# ipro7 register map
Vendor: intelpro; Series: BTBLE
CPU: ipro7, little endian
Registers are 32-bit, read-write, reset 0x0 unless marked. A register's access mark holds for its fields unless they carry their own. Offsets are from the block's base; [hi:lo] are bit positions; {n}, {i} and the like mark numbered series.

## RF
Base 0x30001000
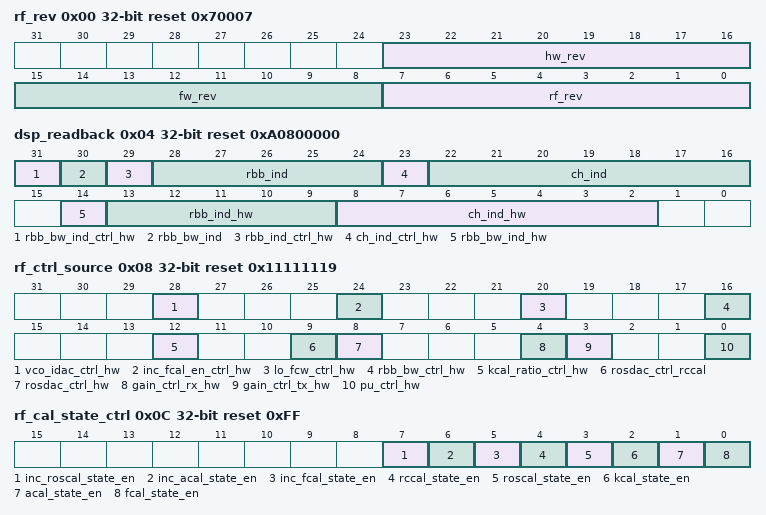
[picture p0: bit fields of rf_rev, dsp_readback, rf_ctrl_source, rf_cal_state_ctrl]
0x00 rf_rev reset 0x70007 (reset mask 0xFF000000) — Silicon revision
  [23:16] hw_rev ro — mark digital HW REV ID
  [15:8] fw_rev ro — mark firmware REV ID
  [7:0] rf_rev ro — mark RF IP rev ID
0x04 dsp_readback reset 0xA0800000 (reset mask 0xFFFF8003)
  [31] rbb_bw_ind_ctrl_hw
  [30] rbb_bw_ind — 0: 1M mode, 1: 2M mode
  [29] rbb_ind_ctrl_hw
  [28:24] rbb_ind — 0: -12dB, 15: 18dB
  [23] ch_ind_ctrl_hw
  [22:16] ch_ind — 0: 2400MHz, 80: 2480MHz
  [14] rbb_bw_ind_hw ro — 0: 1M mode, 1: 2M mode
  [13:9] rbb_ind_hw ro — 0: -12dB, 15: 18dB
  [8:2] ch_ind_hw ro — 0: 2400MHz, 80: 2480MHz
0x08 rf_ctrl_source reset 0x11111119 — Control logic switch
  [28] vco_idac_ctrl_hw — 1: vco_idac input is controlled by dsp 0: vco_idac input is controlled by register
  [24] inc_fcal_en_ctrl_hw — 1: inc_fcal_en input is controlled by dsp 0: inc_fcal_en input is controlled by register
  [20] lo_fcw_ctrl_hw — 1: lo_fcw input is controlled by dsp 0: lo_fcw input is controlled by register
  [16] rbb_bw_ctrl_hw — 1: rbb_bw input is controlled by dsp 0: rbb_bw input is controlled by register
  [12] kcal_ratio_ctrl_hw — 1: kcal_ratio input is controlled by dsp 0: kcal_ratio input is controlled by register
  [9] rosdac_ctrl_rccal — 1: dsp control of rosdac from singen 0: dsp control of rosdac from gain table
  [8] rosdac_ctrl_hw — 1: rosdac input is controlled by dsp 0: rosdac input is controlled by register
  [4] gain_ctrl_rx_hw — 1: RX gain control are controlled by hardware logic input, ex gx_xxx_hw 0: RX gain control bits are controlled by this register map gc_xxx value
  [3] gain_ctrl_tx_hw — 1: TX gain control are controlled by hardware logic input, ex gx_xxx_hw 0: TX gain control bits are controlled by this register map gc_xxx value
  [0] pu_ctrl_hw — 1: pu control bits are controlled by hardware logic input ex: pu_xxx_hw 0: pu control bits are controlled by pu_xxx in this registermap
0x0C rf_cal_state_ctrl reset 0xFF — rf calibration state enable in full cal list
  [7] inc_roscal_state_en — 1'b1: perform inc_roscal
  [6] inc_acal_state_en — 1'b1: perform inc_acal
  [5] inc_fcal_state_en — 1'b1: perform inc_fcal
  [4] rccal_state_en — 1'b1: perform rccal
  [3] roscal_state_en — 1'b1: perform roscal
  [2] kcal_state_en — 1'b1: perform kal
  [1] acal_state_en — 1'b1: perform acal
  [0] fcal_state_en — 1'b1: perform fcal
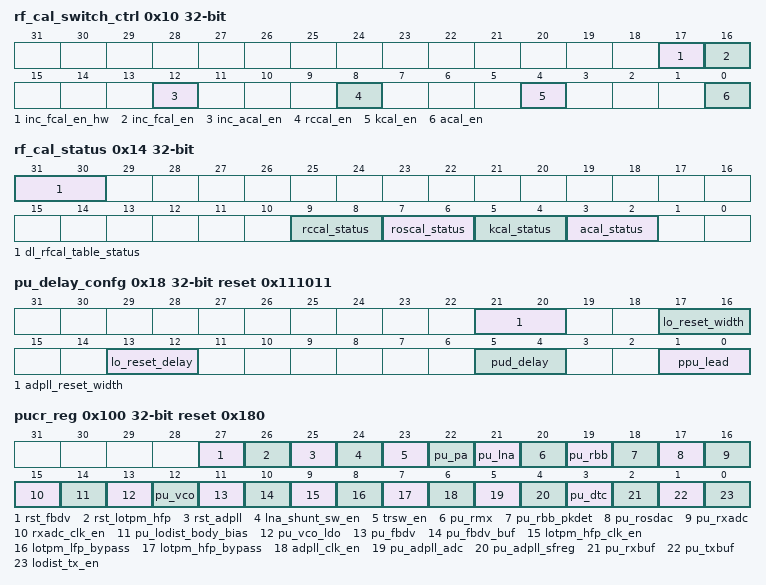
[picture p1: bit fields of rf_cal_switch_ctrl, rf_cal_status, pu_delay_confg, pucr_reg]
0x10 rf_cal_switch_ctrl (reset mask 0xFFFDFFFF) — Calibration mode register
  [17] inc_fcal_en_hw ro
  [16] inc_fcal_en — valid when inc_fcal_en_ctrl_hw=0
  [12] inc_acal_en
  [8] rccal_en
  [4] kcal_en
  [0] acal_en
0x14 rf_cal_status
  [31:30] dl_rfcal_table_status — no calibration, just download RFCAL table status : 0: not started, 1: on-going, 2: fail, 3:pass
  [9:8] rccal_status — 0: not started, 1: on-going, 2: fail, 3:pass
  [7:6] roscal_status — 0: not started, 1: on-going, 2: fail, 3:pass
  [5:4] kcal_status — 0: not started, 1: on-going, 2: fail, 3:pass
  [3:2] acal_status — 0: not started, 1: on-going, 2: fail, 3:pass
0x18 pu_delay_confg reset 0x111011
  [21:20] adpll_reset_width — pulse width of rst_adpll 0: 0.4us, 1: 0.8us, 2: 1.2us, 3: 1.6us
  [17:16] lo_reset_width — pulse width of rst_fbdv/rst_lotpm_hfp/rst_lotpm_lfp 0: 0.1us, 1: 0.2us, 2: 0.3us, 3: 0.4us
  [13:12] lo_reset_delay — lo reset delay WRT ppu_vco 0: 0.4us 1: 0.8us 2: 1.2us 3 1.6us
  [5:4] pud_delay — PUD signal delay with respect to PU 2'b00: 2 us 2'b01: 4 us 2'b10: 6 us 2'b11: 8 us
  [1:0] ppu_lead — PPU signal lead to PU signal 2'b00: 0.2 us 2'b01: 0.4 us 2'b10: 0.6 us 2'b11: 0.8 us
0x100 pucr_reg reset 0x180 — Register control of power up signals
  [27] rst_fbdv — register control, valid when pu_ctrl_hw=0
  [26] rst_lotpm_hfp
  [25] rst_adpll
  [24] lna_shunt_sw_en — 1: ~15dB rx gain att 0: normal mode
  [23] trsw_en — 1: RX mode 0:TX mode
  [22] pu_pa
  [21] pu_lna
  [20] pu_rmx
  [19] pu_rbb
  [18] pu_rbb_pkdet
  [17] pu_rosdac
  [16] pu_rxadc
  [15] rxadc_clk_en
  [14] pu_lodist_body_bias
  [13] pu_vco_ldo
  [12] pu_vco
  [11] pu_fbdv
  [10] pu_fbdv_buf
  [9] lotpm_hfp_clk_en
  [8] lotpm_lfp_bypass
  [7] lotpm_hfp_bypass
  [6] adpll_clk_en
  [5] pu_adpll_adc
  [4] pu_adpll_sfreg
  [3] pu_dtc
  [2] pu_rxbuf
  [1] pu_txbuf
  [0] lodist_tx_en
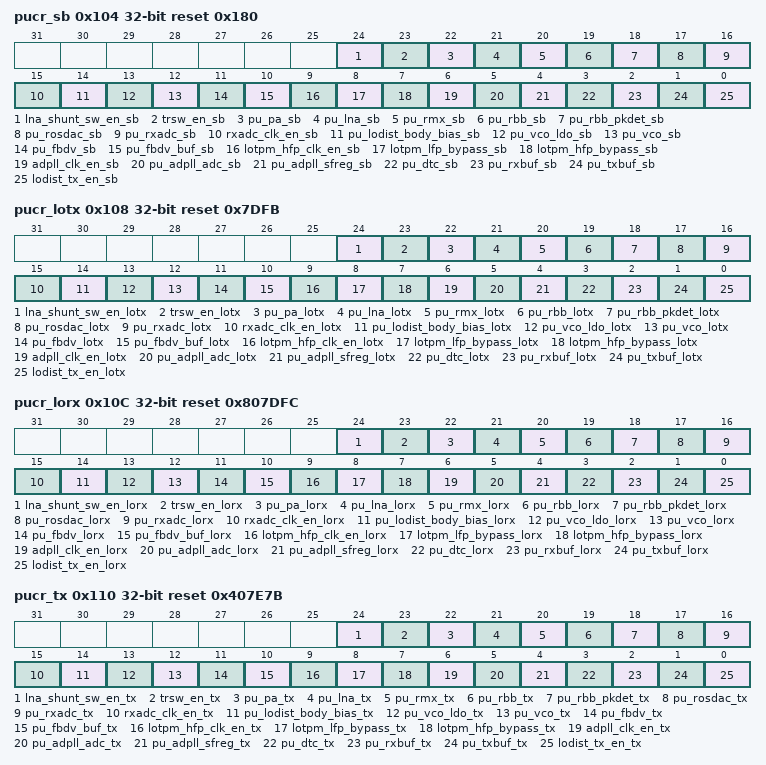
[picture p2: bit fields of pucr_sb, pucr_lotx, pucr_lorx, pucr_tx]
0x104 pucr_sb reset 0x180 — Power up setting in SB state
  [24] lna_shunt_sw_en_sb — 1: ~15dB rx gain att 0: normal mode
  [23] trsw_en_sb
  [22] pu_pa_sb
  [21] pu_lna_sb
  [20] pu_rmx_sb
  [19] pu_rbb_sb
  [18] pu_rbb_pkdet_sb
  [17] pu_rosdac_sb
  [16] pu_rxadc_sb
  [15] rxadc_clk_en_sb
  [14] pu_lodist_body_bias_sb
  [13] pu_vco_ldo_sb
  [12] pu_vco_sb
  [11] pu_fbdv_sb
  [10] pu_fbdv_buf_sb
  [9] lotpm_hfp_clk_en_sb
  [8] lotpm_lfp_bypass_sb
  [7] lotpm_hfp_bypass_sb
  [6] adpll_clk_en_sb
  [5] pu_adpll_adc_sb
  [4] pu_adpll_sfreg_sb
  [3] pu_dtc_sb
  [2] pu_rxbuf_sb
  [1] pu_txbuf_sb
  [0] lodist_tx_en_sb
0x108 pucr_lotx reset 0x7DFB — Power up in LOTX state
  [24] lna_shunt_sw_en_lotx — 1: ~15dB rx gain att 0: normal mode
  [23] trsw_en_lotx
  [22] pu_pa_lotx
  [21] pu_lna_lotx
  [20] pu_rmx_lotx
  [19] pu_rbb_lotx
  [18] pu_rbb_pkdet_lotx
  [17] pu_rosdac_lotx
  [16] pu_rxadc_lotx
  [15] rxadc_clk_en_lotx
  [14] pu_lodist_body_bias_lotx
  [13] pu_vco_ldo_lotx
  [12] pu_vco_lotx
  [11] pu_fbdv_lotx
  [10] pu_fbdv_buf_lotx
  [9] lotpm_hfp_clk_en_lotx
  [8] lotpm_lfp_bypass_lotx
  [7] lotpm_hfp_bypass_lotx
  [6] adpll_clk_en_lotx
  [5] pu_adpll_adc_lotx
  [4] pu_adpll_sfreg_lotx
  [3] pu_dtc_lotx
  [2] pu_rxbuf_lotx
  [1] pu_txbuf_lotx
  [0] lodist_tx_en_lotx
0x10C pucr_lorx reset 0x807DFC — Power up in LORX state
  [24] lna_shunt_sw_en_lorx — 1: ~15dB rx gain att 0: normal mode
  [23] trsw_en_lorx
  [22] pu_pa_lorx
  [21] pu_lna_lorx
  [20] pu_rmx_lorx
  [19] pu_rbb_lorx
  [18] pu_rbb_pkdet_lorx
  [17] pu_rosdac_lorx
  [16] pu_rxadc_lorx
  [15] rxadc_clk_en_lorx
  [14] pu_lodist_body_bias_lorx
  [13] pu_vco_ldo_lorx
  [12] pu_vco_lorx
  [11] pu_fbdv_lorx
  [10] pu_fbdv_buf_lorx
  [9] lotpm_hfp_clk_en_lorx
  [8] lotpm_lfp_bypass_lorx
  [7] lotpm_hfp_bypass_lorx
  [6] adpll_clk_en_lorx
  [5] pu_adpll_adc_lorx
  [4] pu_adpll_sfreg_lorx
  [3] pu_dtc_lorx
  [2] pu_rxbuf_lorx
  [1] pu_txbuf_lorx
  [0] lodist_tx_en_lorx
0x110 pucr_tx reset 0x407E7B — Power up in TX state
  [24] lna_shunt_sw_en_tx — 1: ~15dB rx gain att 0: normal mode
  [23] trsw_en_tx
  [22] pu_pa_tx
  [21] pu_lna_tx
  [20] pu_rmx_tx
  [19] pu_rbb_tx
  [18] pu_rbb_pkdet_tx
  [17] pu_rosdac_tx
  [16] pu_rxadc_tx
  [15] rxadc_clk_en_tx
  [14] pu_lodist_body_bias_tx
  [13] pu_vco_ldo_tx
  [12] pu_vco_tx
  [11] pu_fbdv_tx
  [10] pu_fbdv_buf_tx
  [9] lotpm_hfp_clk_en_tx
  [8] lotpm_lfp_bypass_tx
  [7] lotpm_hfp_bypass_tx
  [6] adpll_clk_en_tx
  [5] pu_adpll_adc_tx
  [4] pu_adpll_sfreg_tx
  [3] pu_dtc_tx
  [2] pu_rxbuf_tx
  [1] pu_txbuf_tx
  [0] lodist_tx_en_tx
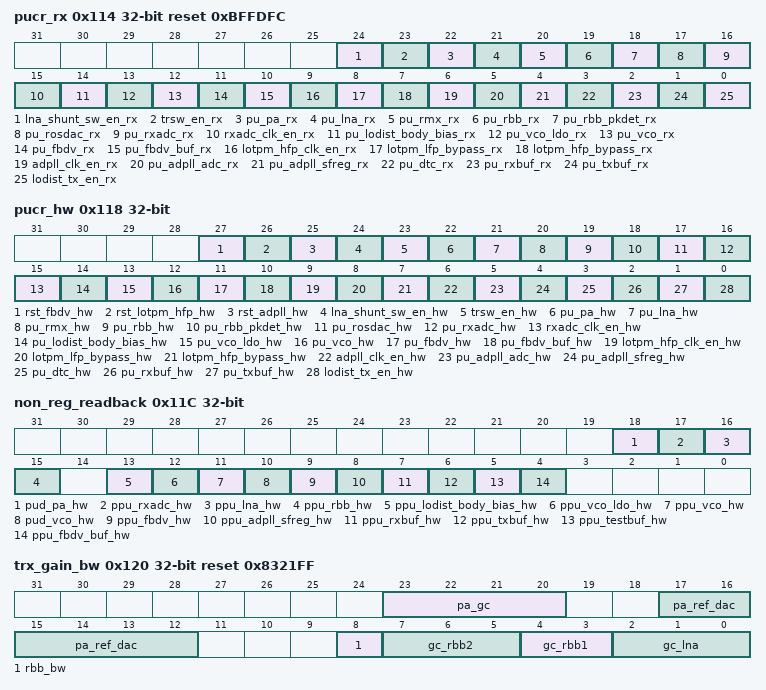
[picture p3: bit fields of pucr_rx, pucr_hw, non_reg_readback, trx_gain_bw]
0x114 pucr_rx reset 0xBFFDFC — Power up in RX state
  [24] lna_shunt_sw_en_rx — 1: ~15dB rx gain att 0: normal mode
  [23] trsw_en_rx
  [22] pu_pa_rx
  [21] pu_lna_rx
  [20] pu_rmx_rx
  [19] pu_rbb_rx
  [18] pu_rbb_pkdet_rx
  [17] pu_rosdac_rx
  [16] pu_rxadc_rx
  [15] rxadc_clk_en_rx
  [14] pu_lodist_body_bias_rx
  [13] pu_vco_ldo_rx
  [12] pu_vco_rx
  [11] pu_fbdv_rx
  [10] pu_fbdv_buf_rx
  [9] lotpm_hfp_clk_en_rx
  [8] lotpm_lfp_bypass_rx
  [7] lotpm_hfp_bypass_rx
  [6] adpll_clk_en_rx
  [5] pu_adpll_adc_rx
  [4] pu_adpll_sfreg_rx
  [3] pu_dtc_rx
  [2] pu_rxbuf_rx
  [1] pu_txbuf_rx
  [0] lodist_tx_en_rx
0x118 pucr_hw (reset mask 0xF0000000) — Hardware read back of power up signals
  [27] rst_fbdv_hw ro — hardware read back
  [26] rst_lotpm_hfp_hw ro — hardware read back
  [25] rst_adpll_hw ro — hardware read back
  [24] lna_shunt_sw_en_hw ro — hardware read back
  [23] trsw_en_hw ro — hardware read back
  [22] pu_pa_hw ro — hardware read back
  [21] pu_lna_hw ro — hardware read back
  [20] pu_rmx_hw ro — hardware read back
  [19] pu_rbb_hw ro — hardware read back
  [18] pu_rbb_pkdet_hw ro — hardware read back
  [17] pu_rosdac_hw ro — hardware read back
  [16] pu_rxadc_hw ro — hardware read back
  [15] rxadc_clk_en_hw ro — hardware read back
  [14] pu_lodist_body_bias_hw ro — hardware read back
  [13] pu_vco_ldo_hw ro — hardware read back
  [12] pu_vco_hw ro — hardware read back
  [11] pu_fbdv_hw ro — hardware read back
  [10] pu_fbdv_buf_hw ro — hardware read back
  [9] lotpm_hfp_clk_en_hw ro — hardware read back
  [8] lotpm_lfp_bypass_hw ro — hardware read back
  [7] lotpm_hfp_bypass_hw ro — hardware read back
  [6] adpll_clk_en_hw ro — hardware read back
  [5] pu_adpll_adc_hw ro — hardware read back
  [4] pu_adpll_sfreg_hw ro — hardware read back
  [3] pu_dtc_hw ro — hardware read back
  [2] pu_rxbuf_hw ro — hardware read back
  [1] pu_txbuf_hw ro — hardware read back
  [0] lodist_tx_en_hw ro — hardware read back
0x11C non_reg_readback (reset mask 0xFFF8400F)
  [18] pud_pa_hw ro — hardware read back
  [17] ppu_rxadc_hw ro — hardware read back
  [16] ppu_lna_hw ro — hardware read back
  [15] ppu_rbb_hw ro — hardware read back
  [13] ppu_lodist_body_bias_hw ro — hardware read back
  [12] ppu_vco_ldo_hw ro — hardware read back
  [11] ppu_vco_hw ro — hardware read back
  [10] pud_vco_hw ro — hardware read back
  [9] ppu_fbdv_hw ro — hardware read back
  [8] ppu_adpll_sfreg_hw ro — hardware read back
  [7] ppu_rxbuf_hw ro — hardware read back
  [6] ppu_txbuf_hw ro — hardware read back
  [5] ppu_testbuf_hw ro — hardware read back
  [4] ppu_fbdv_buf_hw ro — hardware read back
0x120 trx_gain_bw reset 0x8321FF — Register control of TX/RX gain
  [23:20] pa_gc — pa gain code
  [17:12] pa_ref_dac — default maximum 1c
  [8] rbb_bw — 0: 1M mode, 1: 2M mode, valid when rbb_bw_ctrl_hw=0
  [7:5] gc_rbb2 — 3'b000:-6dB, 3'b001:-4dB, 3'b010:-2dB, 3'b011:0dB 3'b100:2dB, 3'b101:4dB, 3'b110:6dB, 3'b111:8dB
  [4:3] gc_rbb1 — 1'b00:-6dB, 1'b01:0dB, 1'b10:6dB, 1'b11:rsvd
  [2:0] gc_lna — lna gain code register control, valid when gain_ctrl_hw=0 3'b7 54dB 3'b6 48dB 3'b5 42dB 3'b4 36dB 3'b3 30dB 3'b2 24dB 3'b1 18dB3'b0 12dB
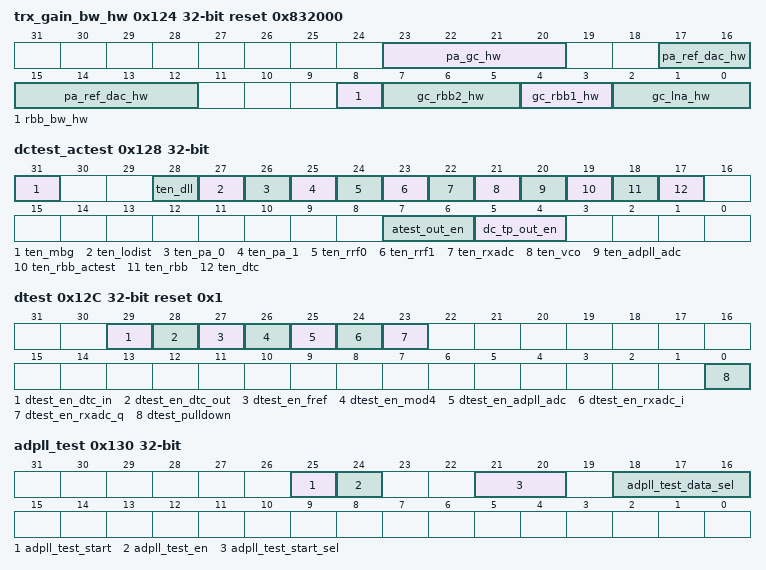
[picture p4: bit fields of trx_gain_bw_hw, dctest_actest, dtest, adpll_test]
0x124 trx_gain_bw_hw reset 0x832000 (reset mask 0xFF0C0E00) — Hardware read back of TX/RX gain
  [23:20] pa_gc_hw ro — pa gain code
  [17:12] pa_ref_dac_hw ro
  [8] rbb_bw_hw ro — 0: 1M mode, 1: 2M mode
  [7:5] gc_rbb2_hw ro — 3'b000:-6dB, 3'b001:-4dB, 3'b010:-2dB, 3'b011:0dB 3'b100:2dB, 3'b101:4dB, 3'b110:6dB, 3'b111:8dB
  [4:3] gc_rbb1_hw ro — 1'b00:-6dB, 1'b01:0dB, 1'b10:6dB, 1'b11:rsvd
  [2:0] gc_lna_hw ro — lna gain code register control 3'b7 54dB 3'b6 48dB 3'b5 42dB 3'b4 36dB 3'b3 30dB 3'b2 24dB 3'b1 18dB3'b0 12dB
0x128 dctest_actest — DC Test register 0
  [31] ten_mbg
  [28] ten_dll
  [27] ten_lodist
  [26] ten_pa_0
  [25] ten_pa_1
  [24] ten_rrf0
  [23] ten_rrf1
  [22] ten_rxadc
  [21] ten_vco
  [20] ten_adpll_adc
  [19] ten_rbb_actest
  [18] ten_rbb
  [17] ten_dtc
  [7:6] atest_out_en — 1'b1: enable RX ac test switch to PAD
  [5:4] dc_tp_out_en — 1'b1: enable dc test switch to PAD
0x12C dtest reset 0x1 — LO Bias Mode registers
  [29] dtest_en_dtc_in, [28] dtest_en_dtc_out, [27] dtest_en_fref, [26] dtest_en_mod4, [25] dtest_en_adpll_adc, [24] dtest_en_rxadc_i, [23] dtest_en_rxadc_q, [0] dtest_pulldown
0x130 adpll_test (reset mask 0xFDFFFFFF)
  [25] adpll_test_start ro
  [24] adpll_test_en — enable adpll dtest
  [21:20] adpll_test_start_sel — select the start signal of the dtest block 2'b00, observe the FSM behavior 2'b01, observe FCAL behavior 2'b10, observe the INC_FCAL behavior 2'b11, observe the LMS behavior
  [18:16] adpll_test_data_sel — dtest block mux select
0x134 adpll_test2 reset not defined
  [31:0] adpll_test_out ro
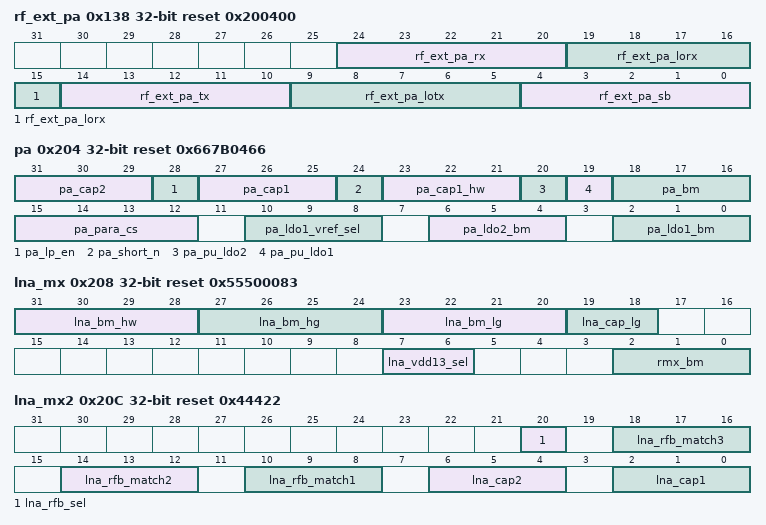
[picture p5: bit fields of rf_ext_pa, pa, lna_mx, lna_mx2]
0x138 rf_ext_pa reset 0x200400
  [24:20] rf_ext_pa_rx, [19:15] rf_ext_pa_lorx, [14:10] rf_ext_pa_tx, [9:5] rf_ext_pa_lotx, [4:0] rf_ext_pa_sb
0x200 cip_ldo15 reset 0x2
  [1:0] vg11_sel — vg13-vg11 delta voltage. 0: 0.15V, 1: 0.2V, 2: 0.25V, 3: 0.3V
0x204 pa reset 0x667B0466 (reset mask 0xFF1FFFFF)
  [31:29] pa_cap2
  [28] pa_lp_en — [pa_hp_en, pa_lp_en]: 2'b00 10dBm, 2'b10 14dBm, 2'b01 0dBm
  [27:25] pa_cap1
  [24] pa_short_n
  [23:21] pa_cap1_hw ro
  [20] pa_pu_ldo2
  [19] pa_pu_ldo1
  [18:16] pa_bm — pa nmos bias sel
  [15:12] pa_para_cs — 0: 0dBm/10dBm, 3:14dBm
  [10:8] pa_ldo1_vref_sel
  [6:4] pa_ldo2_bm — 3'b000 lowest current ~ 3'b111 highest current
  [2:0] pa_ldo1_bm — 3'b000 lowest current ~ 3'b111 highest current
0x208 lna_mx reset 0x55500083 (reset mask 0xFFFFFFF) — LNA mixer register
  [31:28] lna_bm_hw ro — lna bias mode readback
  [27:24] lna_bm_hg — lna bias mode control in high gain 8: 1.3mA, 3: 0.9mA
  [23:20] lna_bm_lg — lna bias mode control in low gain 8: 0.4mA, 3: 0.3mA
  [19:18] lna_cap_lg — lg matching cap selection, 0: 0fF, 1: 50fF, 2: 50fF, 3: 100fF
  [7:6] lna_vdd13_sel
  [2:0] rmx_bm — 0: 0.75V, 1: 0.8V, 2: 0.85V, 3: 0.9V, 4: 0.95V, 5: 1V, 6: 1.05V, 7: 1.1V
0x20C lna_mx2 reset 0x44422 — LNA mixer register
  [20] lna_rfb_sel, [18:16] lna_rfb_match3, [14:12] lna_rfb_match2, [10:8] lna_rfb_match1, [6:4] lna_cap2, [2:0] lna_cap1
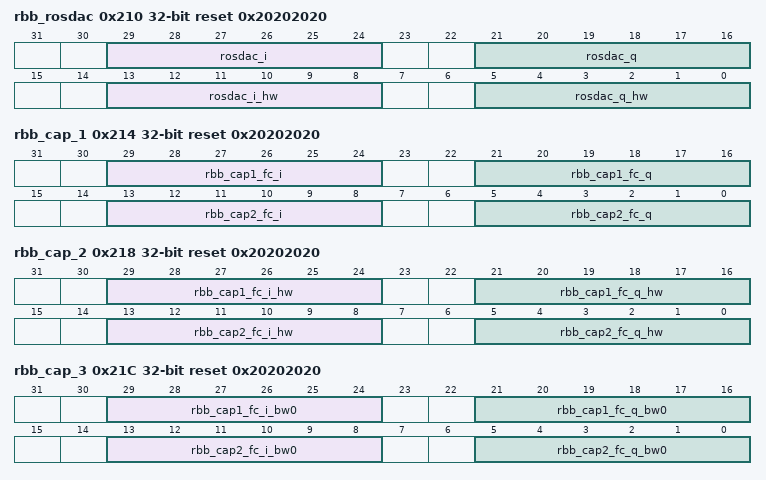
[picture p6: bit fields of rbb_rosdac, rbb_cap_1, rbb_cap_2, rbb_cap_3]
0x210 rbb_rosdac reset 0x20202020 (reset mask 0xFFFFC0C0)
  [29:24] rosdac_i — resister control of rosdac_i, valid when rosdac_ctrl_hw=0
  [21:16] rosdac_q — resister control of rosdac_q, valid when rosdac_ctrl_hw=0
  [13:8] rosdac_i_hw ro — rosdac_i readback
  [5:0] rosdac_q_hw ro — rosdac_q readback
0x214 rbb_cap_1 reset 0x20202020
  [29:24] rbb_cap1_fc_i — capbank tuning for TIA I channel, valid when rbb_cap_ctrl_hw=0
  [21:16] rbb_cap1_fc_q — capbank tuning for TIA Q channel,valid when rbb_cap_ctrl_hw=0
  [13:8] rbb_cap2_fc_i — capbank tuning for BQ I channel, valid when rbb_cap_ctrl_hw=0
  [5:0] rbb_cap2_fc_q — capbank tuning for BQ Q channel,valid when rbb_cap_ctrl_hw=0
0x218 rbb_cap_2 reset 0x20202020 (reset mask 0xC0C0C0C0)
  [29:24] rbb_cap1_fc_i_hw ro — capbank tuning for TIA I channel readback
  [21:16] rbb_cap1_fc_q_hw ro — capbank tuning for TIA Q channel readback
  [13:8] rbb_cap2_fc_i_hw ro — capbank tuning for BQ I channel readback
  [5:0] rbb_cap2_fc_q_hw ro — capbank tuning for BQ Q channel readback
0x21C rbb_cap_3 reset 0x20202020
  [29:24] rbb_cap1_fc_i_bw0 — capbank tuning for TIA I channel @ 1M BW mode
  [21:16] rbb_cap1_fc_q_bw0 — capbank tuning for TIA Q channel @ 1M BW mode
  [13:8] rbb_cap2_fc_i_bw0 — capbank tuning for BQ I channel @ 1M BW mode
  [5:0] rbb_cap2_fc_q_bw0 — capbank tuning for BQ Q channel @ 1M BW mode
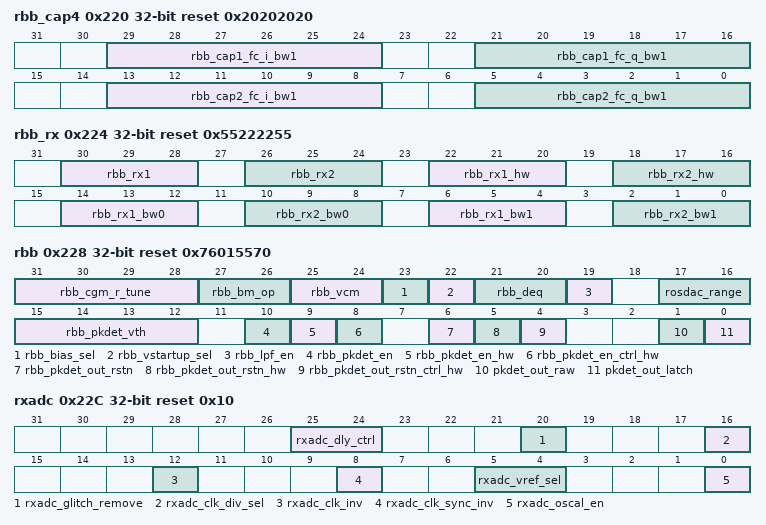
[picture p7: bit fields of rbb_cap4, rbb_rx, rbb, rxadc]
0x220 rbb_cap4 reset 0x20202020
  [29:24] rbb_cap1_fc_i_bw1 — capbank tuning for TIA I channel @ 2M BW mode
  [21:16] rbb_cap1_fc_q_bw1 — capbank tuning for TIA Q channel @ 2M BW mode
  [13:8] rbb_cap2_fc_i_bw1 — capbank tuning for BQ I channel @ 2M BW mode
  [5:0] rbb_cap2_fc_q_bw1 — capbank tuning for BQ Q channel @ 2M BW mode
0x224 rbb_rx reset 0x55222255 (reset mask 0xFF88FFFF)
  [30:28] rbb_rx1 — rbb_rx1 register ctrl, valid when rbb_bw_ctrl_hw=0
  [26:24] rbb_rx2 — rbb_rx2 register ctrl, valid when rbb_bw_ctrl_hw=0
  [22:20] rbb_rx1_hw ro — rbb_rx1 readback @ digital/rf interface
  [18:16] rbb_rx2_hw ro — rbb_rx2 readback @ digital/rf interface
  [14:12] rbb_rx1_bw0 — rbb_rx1 register config @ 1M BW mode, valid when rbb_bw_index=0 and rbb_bw_ctrl_hw=1
  [10:8] rbb_rx2_bw0 — rbb_rx2 register config @ 1M BW mode, valid when rbb_bw_index=0 and rbb_bw_ctrl_hw=1
  [6:4] rbb_rx1_bw1 — rbb_rx1 register config @ 2M BW mode, valid when rbb_bw_index=1 and rbb_bw_ctrl_hw=1
  [2:0] rbb_rx2_bw1 — rbb_rx2 register config @ 2M BW mode, valid when rbb_bw_index=1 and rbb_bw_ctrl_hw=1
0x228 rbb reset 0x76015570 (reset mask 0xFFFFFDDC)
  [31:28] rbb_cgm_r_tune
  [27:26] rbb_bm_op — 0: 75%, 1: 100%, 2: 125%, 3: 150%
  [25:24] rbb_vcm — rbb vcm: 2'b00: 650mV, 2'b01:700mV, 2'b10:750mV, 2'b11:800mV
  [23] rbb_bias_sel
  [22] rbb_vstartup_sel
  [21:20] rbb_deq — Decrease Q of biquad
  [19] rbb_lpf_en — config RBB as low pass filter for RCCAL
  [17:16] rosdac_range
  [15:12] rbb_pkdet_vth — 0:-4dBm, 1:-2dBm, 2:-1dBm … 13:10dBm, 14:not valid, 15:not valid
  [10] rbb_pkdet_en — register control of rbb pkdet enable
  [9] rbb_pkdet_en_hw ro — readback of rbb pkdet enable
  [8] rbb_pkdet_en_ctrl_hw — rbb pkdet enable source, 1: from dsp, 0: from register
  [6] rbb_pkdet_out_rstn — register control of reset of rbb pkdet output RS latch
  [5] rbb_pkdet_out_rstn_hw ro — readback of reset of rbb pkdet output RS latch
  [4] rbb_pkdet_out_rstn_ctrl_hw — rbb pkdet reset source, 1: from dsp, 0: from register
  [1] pkdet_out_raw ro — rbb pkdet output raw signal
  [0] pkdet_out_latch ro — rbb pkdet output signal after RS latch
0x22C rxadc reset 0x10
  [25:24] rxadc_dly_ctrl
  [20] rxadc_glitch_remove
  [16] rxadc_clk_div_sel — 1'b0: 32M 1'b1: 16M
  [12] rxadc_clk_inv — 1'b0: non_invert 1'b1: Invert
  [8] rxadc_clk_sync_inv — 1'b0: falling edge synchronize data 1'b1: rising edge synchronize data
  [5:4] rxadc_vref_sel — 0: 1.38V, 1: 1.45V, 2: 1.52V 3: 1.6V (Differential peak-to-peak)
  [0] rxadc_oscal_en
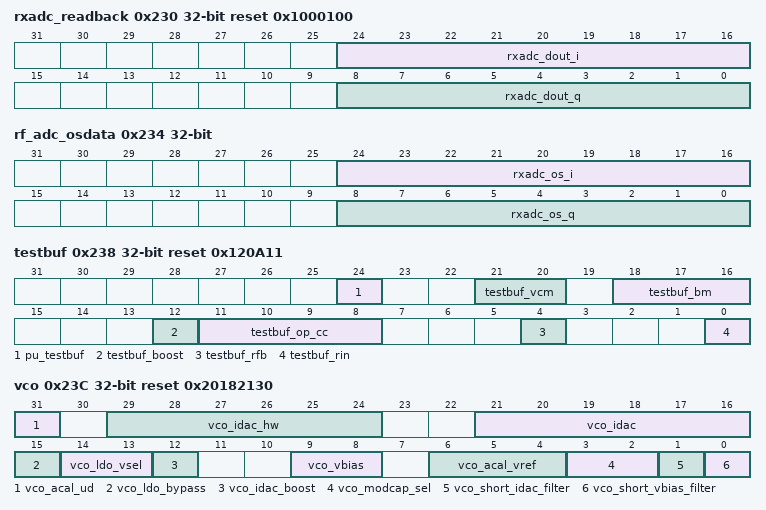
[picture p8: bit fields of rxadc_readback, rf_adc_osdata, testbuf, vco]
0x230 rxadc_readback reset 0x1000100 (reset mask 0xFE00FE00)
  [24:16] rxadc_dout_i ro — record rf adc output value in register
  [8:0] rxadc_dout_q ro — record rf adc output value in register
0x234 rf_adc_osdata
  [24:16] rxadc_os_i — 9bit signed
  [8:0] rxadc_os_q — 9bit signed
0x238 testbuf reset 0x120A11
  [24] pu_testbuf
  [21:20] testbuf_vcm — 0: 0.65V, 1: 0.7V, 2: 0.75V, 3: 0.8V
  [18:16] testbuf_bm — 0: 0.5x, 1: 0.75x, 2: 1x, 3: 1.25x
  [12] testbuf_boost — 2x current for opamp output stage
  [11:8] testbuf_op_cc — opamp compensation cap
  [4] testbuf_rfb — 0: 5k, 1: 10k
  [0] testbuf_rin — 0: 5k, 1: 10k
0x23C vco reset 0x20182130 (reset mask 0x40FFFFFF)
  [31] vco_acal_ud ro — 1: vco amplitude > threshold voltage
  [29:24] vco_idac_hw ro — vco_idac readback
  [21:16] vco_idac
  [15] vco_ldo_bypass — 1: bypass vco ldo
  [14:13] vco_ldo_vsel — 0: 1.286V, 1: 1.311V, 2: 1.36V, 3: 1.38V
  [12] vco_idac_boost — extra current for vco core
  [9:8] vco_vbias — 0: 40mV, 1: 80mV, 2: 120mV, 3: 160mV
  [6:4] vco_acal_vref
  [3:2] vco_modcap_sel — 0: 1x modcap, 1: 2x modcap, 2: 3x modcap, 3: 4x modcap
  [1] vco_short_idac_filter — short idac gate resistor
  [0] vco_short_vbias_filter — short varactor bias rc filter resistor
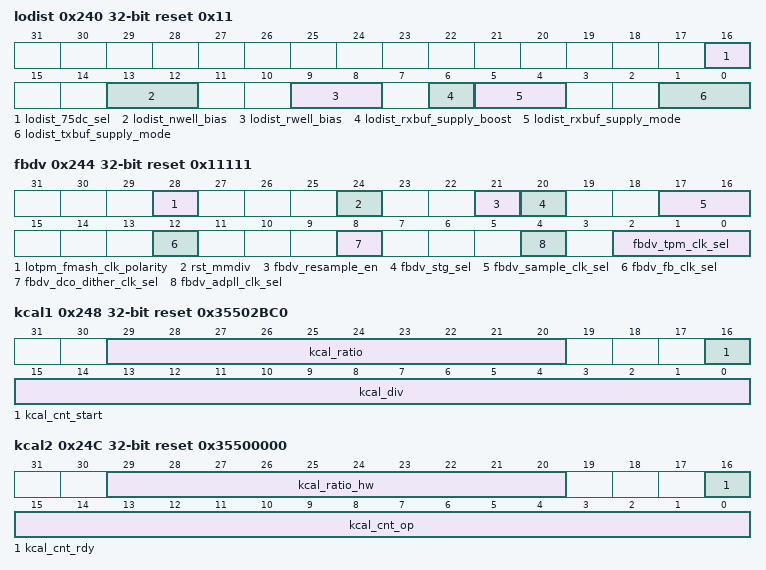
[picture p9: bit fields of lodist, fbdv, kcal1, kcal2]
0x240 lodist reset 0x11
  [16] lodist_75dc_sel — 0: tx clk single output; 1: tx clk differential output
  [13:12] lodist_nwell_bias — 0: nwell bias voltage=rvdd; 3: nwell bias voltage=rvdd-0.3
  [9:8] lodist_rwell_bias — 0: rwell bias voltage=vss; 3: rwell bias voltage=vss+0.3
  [6] lodist_rxbuf_supply_boost — extra way to raise rvdd11 of rxbuf
  [5:4] lodist_rxbuf_supply_mode — 3: highest rvdd11 of rxbuf
  [1:0] lodist_txbuf_supply_mode — 3: highest rvdd11 of txbuf
0x244 fbdv reset 0x11111
  [28] lotpm_fmash_clk_polarity — default 0
  [24] rst_mmdiv — Only need manual control for debug
  [21] fbdv_resample_en
  [20] fbdv_stg_sel — 0: select sample clock from fbdv_ratio, 1: select sample clock from sel_sample_clk
  [17:16] fbdv_sample_clk_sel — 0: mod3, dividing ratio [16,63), 1: mod4, dividing ratio [32,127), 3,4: mod5, dividing ratio [64,255)
  [12] fbdv_fb_clk_sel — 0: mod1, 1: mod1 with pulse width enlarged
  [8] fbdv_dco_dither_clk_sel — 0: co4, 1: co3
  [4] fbdv_adpll_clk_sel — 0: mod4, 1: mod3
  [2:0] fbdv_tpm_clk_sel — select lotpm mash clock, 1: co3, 2: fvco/16, 4: dll output
0x248 kcal1 reset 0x35502BC0
  [29:20] kcal_ratio, [16] kcal_cnt_start, [15:0] kcal_div
0x24C kcal2 reset 0x35500000 (reset mask 0xC00E0000)
  [29:20] kcal_ratio_hw ro, [16] kcal_cnt_rdy ro, [15:0] kcal_cnt_op ro
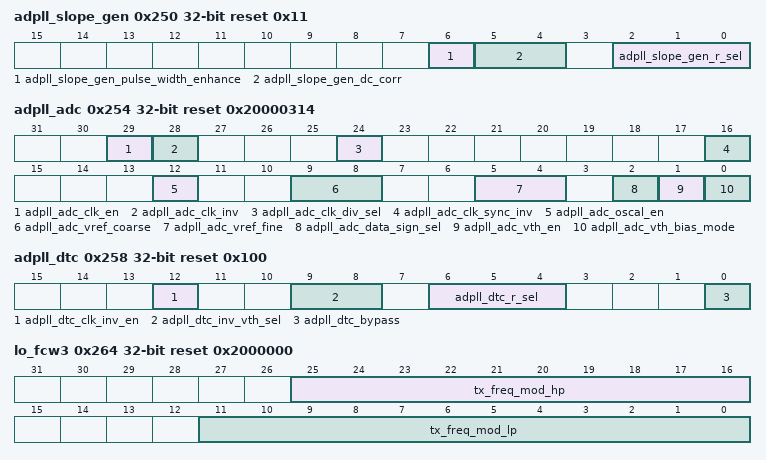
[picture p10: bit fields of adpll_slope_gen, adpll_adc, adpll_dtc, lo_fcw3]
0x250 adpll_slope_gen reset 0x11
  [6] adpll_slope_gen_pulse_width_enhance — Widen the output signal pulse width
  [5:4] adpll_slope_gen_dc_corr — Tune the diff output cross voltage for ADC common mode voltage requirement
  [2:0] adpll_slope_gen_r_sel — Tune the output slope, 0 -> 3 corresponded to slope decrease
0x254 adpll_adc reset 0x20000314
  [29] adpll_adc_clk_en
  [28] adpll_adc_clk_inv — 1'b0: non_invert 1'b1: Invert
  [24] adpll_adc_clk_div_sel — 1'b0: 32M 1'b1: 16M
  [16] adpll_adc_clk_sync_inv — 1'b0: falling edge synchronize data 1'b1: rising edge synchronize data
  [12] adpll_adc_oscal_en
  [9:8] adpll_adc_vref_coarse — Vpp diff 0: 0.6V, 1: 0.9V, 2: 1.2V, 3: 1.5V
  [5:4] adpll_adc_vref_fine — 0: 0.85x, 1: 0.9x, 2: 0.95x, 3: 1x
  [2] adpll_adc_data_sign_sel — 1'b0: unsigned data 1'b1: signed data
  [1] adpll_adc_vth_en
  [0] adpll_adc_vth_bias_mode
0x258 adpll_dtc reset 0x100
  [12] adpll_dtc_clk_inv_en
  [9:8] adpll_dtc_inv_vth_sel — no use
  [6:4] adpll_dtc_r_sel — coarse tune the drc lsb delay, 0->3 for lsb increase
  [0] adpll_dtc_bypass — bypass dtc, reset the dtc_cw to 0
0x25C lo_fc_config1 reset 0x962000
  [24:0] lo_fcw — flo/fxtal*2^17, valid when lo_fcw_ctrl_hw=0
0x260 lo_fcw_config2 reset 0x9B0000 (reset mask 0xFE000000)
  [24:0] lo_fcw_hw ro
0x264 lo_fcw3 reset 0x2000000 (reset mask 0xFC00F000)
  [25:16] tx_freq_mod_hp ro, [11:0] tx_freq_mod_lp ro
0x268 lo_fcw4 reset 0x7F
  [16:0] lo_fcw_frac_th — for phy to compare lo_fcw_chnl_tbl[16:0]<lo_fcw_frac_th[16:0]
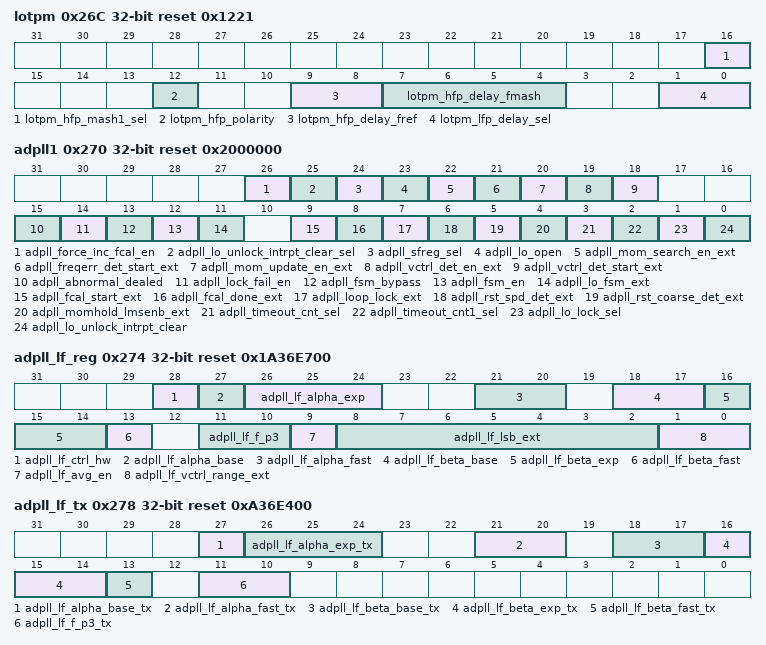
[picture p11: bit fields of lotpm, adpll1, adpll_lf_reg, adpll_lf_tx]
0x26C lotpm reset 0x1221
  [16] lotpm_hfp_mash1_sel — 0: default, 1: use mash1 as hfp mash
  [12] lotpm_hfp_polarity — 1: default, 0: invert output bitwise
  [9:8] lotpm_hfp_delay_fref — default 2
  [7:4] lotpm_hfp_delay_fmash — default 2
  [1:0] lotpm_lfp_delay_sel — default 1
0x270 adpll1 reset 0x2000000
  [26] adpll_force_inc_fcal_en
  [25] adpll_lo_unlock_intrpt_clear_sel — 0: auto clear, 1: manual clear
  [24] adpll_sfreg_sel — Turn on the extral sfreg units in the adpll_sfreg block
  [23] adpll_lo_open — enable lo open, vctrl and momcap code all come from digital registers
  [22] adpll_mom_search_en_ext — software FCAL enable, fcal_mode should be set to 2 or 3 for external control momcap code
  [21] adpll_freqerr_det_start_ext — start frequency error detection when be 1'b1, valid at adpll_mom_search_en_ext = 1'b1
  [20] adpll_mom_update_en_ext — Software incremental FCAL enable, mom_code should be from external register
  [19] adpll_vctrl_det_en_ext — Software incremental FCAL enable, enable vctrl out of range detection
  [18] adpll_vctrl_det_start_ext — start vctrl out of range detection, valid at adpll_vctrl_det_en_ext = 1'b1
  [15] adpll_abnormal_dealed — 1'b1 for adpll fsm turn around when FCAL is failed due to mom_code overflow or lock failed
  [14] adpll_lock_fail_en — 1'b1 enable the lock fail indicator to let the fsm go to state 10 (ADPLL_FAIL)
  [13] adpll_fsm_bypass
  [12] adpll_fsm_en — 1'b1 Enable the ADPLL FSM
  [11] adpll_lo_fsm_ext — 1'b1 enable the external FSM control
  [9] adpll_fcal_start_ext — valid when adpll_lo_fsm_ext = 1, start the FCAL
  [8] adpll_fcal_done_ext — valid when adpll_lo_fsm_ext = 1, fcal done signal
  [7] adpll_loop_lock_ext — valid when adpll_lo_fsm_ext = 1, loop locked signal
  [6] adpll_rst_spd_det_ext — valid when adpll_lo_fsm_ext = 1, reset spd detection block
  [5] adpll_rst_coarse_det_ext
  [4] adpll_momhold_lmsenb_ext
  [3] adpll_timeout_cnt_sel — The main timeout value for FCAL and loop lock
  [2] adpll_timeout_cnt1_sel — timeout value for internal reset control
  [1] adpll_lo_lock_sel — select the lo lock signal, 1'b1 means state 5 or 9 is locked, 1'b0 means only state 5 is locked
  [0] adpll_lo_unlock_intrpt_clear — manually clear unlock interupt signal when 1'b1
0x274 adpll_lf_reg reset 0x1A36E700
  [28] adpll_lf_ctrl_hw
  [27] adpll_lf_alpha_base — change the alpha by 2^alpha_base_sel, could be 0, 1
  [26:24] adpll_lf_alpha_exp — change the alpha by 2^(2*alpha_exp_sel),could be 0, 1, 2, 3, 4, 5
  [21:20] adpll_lf_alpha_fast — in fast lock state, alpha can be enlarge by 2^(alpha_fast_sel), could be 0, 1, 2, 3
  [18:17] adpll_lf_beta_base — 0,1,2,3 correspond to gain of 0.625, 0.75, 0.875, 1
  [16:14] adpll_lf_beta_exp — change the alpha by 2^beta_exp_sel, could be 0, 1, 2, 3, 4, 5
  [13] adpll_lf_beta_fast — in fast lock state, beta can be enlarge by 2^(beta_fast_sel), could be 0, 1
  [11:10] adpll_lf_f_p3 — can be 0,0.25,0.5,0.75, when it is 0, means turn off the IIR filter
  [9] adpll_lf_avg_en — '1' enable 0.5*(1-z^(-2)) at proportion path
  [8:2] adpll_lf_lsb_ext — xternal value of DVAR control word
  [1:0] adpll_lf_vctrl_range_ext — 2'b00: 48~80, 2'b01: 32~96, 2'b10: 16~112, 2'b11: 1~126
0x278 adpll_lf_tx reset 0xA36E400
  [27] adpll_lf_alpha_base_tx, [26:24] adpll_lf_alpha_exp_tx, [21:20] adpll_lf_alpha_fast_tx, [18:17] adpll_lf_beta_base_tx, [16:14] adpll_lf_beta_exp_tx, [13] adpll_lf_beta_fast_tx, [11:10] adpll_lf_f_p3_tx
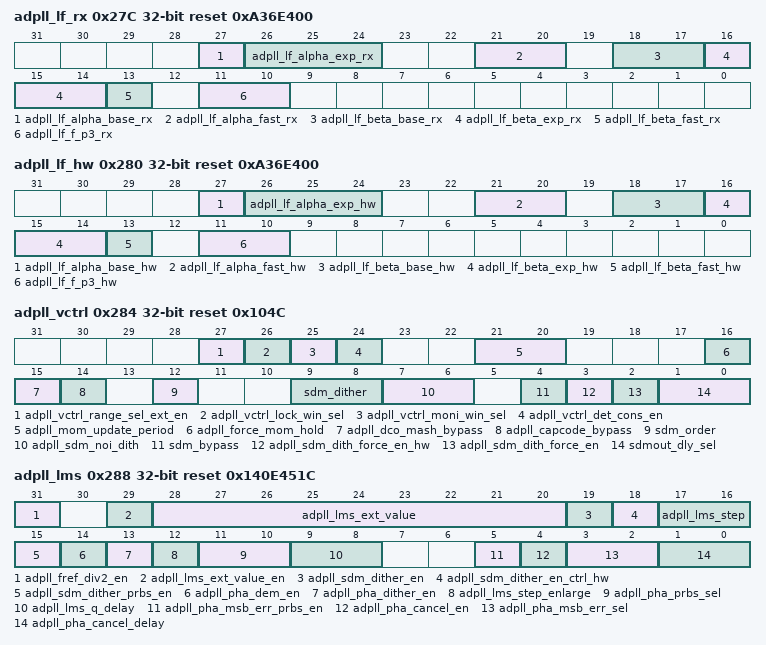
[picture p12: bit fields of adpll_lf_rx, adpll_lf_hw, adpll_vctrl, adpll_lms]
0x27C adpll_lf_rx reset 0xA36E400
  [27] adpll_lf_alpha_base_rx, [26:24] adpll_lf_alpha_exp_rx, [21:20] adpll_lf_alpha_fast_rx, [18:17] adpll_lf_beta_base_rx, [16:14] adpll_lf_beta_exp_rx, [13] adpll_lf_beta_fast_rx, [11:10] adpll_lf_f_p3_rx
0x280 adpll_lf_hw reset 0xA36E400 (reset mask 0xF0C813FF)
  [27] adpll_lf_alpha_base_hw ro, [26:24] adpll_lf_alpha_exp_hw ro, [21:20] adpll_lf_alpha_fast_hw ro, [18:17] adpll_lf_beta_base_hw ro, [16:14] adpll_lf_beta_exp_hw ro, [13] adpll_lf_beta_fast_hw ro, [11:10] adpll_lf_f_p3_hw ro
0x284 adpll_vctrl reset 0x104C (reset mask 0xFFFFFFF7)
  [27] adpll_vctrl_range_sel_ext_en — enable external vctrl detector range selection
  [26] adpll_vctrl_lock_win_sel — '0' for 48~80, '1' for 32~96, decide the lock detect range
  [25] adpll_vctrl_moni_win_sel — '0' for 16~112, '1' for 32~96, decide the lock detect range
  [24] adpll_vctrl_det_cons_en — 1'b1 detect the LF output if it is out of range with consecutive given periods
  [21:20] adpll_mom_update_period — 00'for adaptive one, '01' 8*Tref, '10' 16*Tref,'11' 31*Tref
  [16] adpll_force_mom_hold — force momcap code hold, disable the fine tune of momcap
  [15] adpll_dco_mash_bypass — bypass the dco mash1, for debug
  [14] adpll_capcode_bypass — bypass momcap code, set the code by digital register value, software control
  [12] sdm_order — 0' 1st order, '1' 2rd order
  [9:8] sdm_dither — 0,1,2,3 for 1/2^17,5/2^17,21/2^17,85/2^17
  [7:6] adpll_sdm_noi_dith
  [4] sdm_bypass — bypass fractural part of the divide ratio
  [3] adpll_sdm_dith_force_en_hw ro
  [2] adpll_sdm_dith_force_en
  [1:0] sdmout_dly_sel — select the SDM out delay, for matching the phase cancel path (DTC path) delay
0x288 adpll_lms reset 0x140E451C
  [31] adpll_fref_div2_en — 0: 32M, 1:16M
  [29] adpll_lms_ext_value_en — enable external lms coefficient
  [28:20] adpll_lms_ext_value — digital register lms coefficient value
  [19] adpll_sdm_dither_en
  [18] adpll_sdm_dither_en_ctrl_hw
  [17:16] adpll_lms_step — LMS steady state step, '1' for 2^-11, '2' for 2^-9, '3' for 2^-7, '0' for disable LMS
  [15] adpll_sdm_dither_prbs_en
  [14] adpll_pha_dem_en
  [13] adpll_pha_dither_en
  [12] adpll_lms_step_enlarge — Fast LMS convergence step, '0' for steady_step*2^4, and '1' for 2^5
  [11:10] adpll_pha_prbs_sel
  [9:8] adpll_lms_q_delay — choose the delay on the q path of LMS block for delay matching
  [5] adpll_pha_msb_err_prbs_en
  [4] adpll_pha_cancel_en — enable phase error cancellation
  [3:2] adpll_pha_msb_err_sel
  [1:0] adpll_pha_cancel_delay — choose the delay on the phase cancel data for delay matching
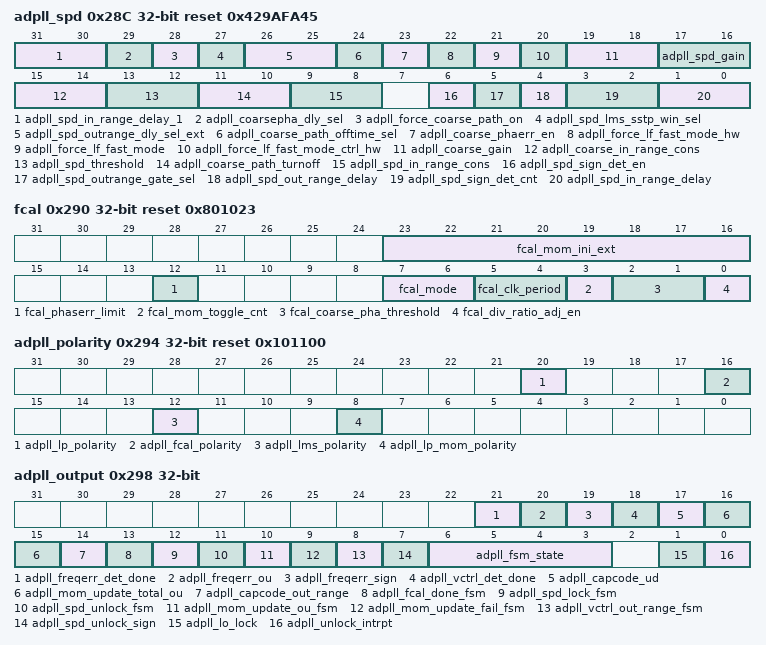
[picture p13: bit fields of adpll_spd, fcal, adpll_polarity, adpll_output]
0x28C adpll_spd reset 0x429AFA45 (reset mask 0xFFBFFFFF)
  [31:30] adpll_spd_in_range_delay_1 — '0' 128*Tref, '1' 256*Tref, '2' 512*Tref, '3' 1023*Tref, minimum LMS large step induce time
  [29] adpll_coarsepha_dly_sel — select the delay of the coarse phase error path, aviod metastability
  [28] adpll_force_coarse_path_on — force the coarse phase detector path on
  [27] adpll_spd_lms_sstp_win_sel — select the small_step window, 0 for 63*Tref, 1 for 127*Tref
  [26:25] adpll_spd_outrange_dly_sel_ext — 0,1,2,3 for 64,128,192,255*Tref, gated the SPD un-within given range by N*Tref time
  [24] adpll_coarse_path_offtime_sel — 1'b0: turnoff coarse path at LMS enable, 1'b1: turnoff at switching LMS and LF MODE
  [23] adpll_coarse_phaerr_en — 0' disable the coarse path phase error at loop capture procedure
  [22] adpll_force_lf_fast_mode_hw ro — PA ramping controled signal, for VCO pulling
  [21] adpll_force_lf_fast_mode — force the LF in the fast lock mode, valid when adpll_force_lf_fast_mode_ctrl_hw=0
  [20] adpll_force_lf_fast_mode_ctrl_hw — enable hardware control
  [19:18] adpll_coarse_gain — 0,1,2,3 for gain of 0.25,0.5,0.75,0.75
  [17:16] adpll_spd_gain — 0,1,2,3 for 2/2^10, 3/2^10, 4/2^10, 5/2^10, match the adc_ref of 0.3,0.45,0.6,0.75 respectively
  [15:14] adpll_coarse_in_range_cons — 0 for 128 cycle, 1 for 256 cycle, 2 for 512, 3 for 1023
  [13:12] adpll_spd_threshold — 0,1,2,3 for 0.125,0.1875,0.25,0.375 respectively
  [11:10] adpll_coarse_path_turnoff — 00 for coarse_phaerr detect, 01 for spd_detect, 10 for or, 11 for and
  [9:8] adpll_spd_in_range_cons — selecting the consecutive periods of the spd output within the given range, 8,16,32,63 periods
  [6] adpll_spd_sign_det_en — enable the detection of the coarse and fine path sign
  [5] adpll_spd_outrange_gate_sel — 0 for lms_en = 1,disable the out of range detection. 1 select the fsm_loop_lock
  [4] adpll_spd_out_range_delay — 1'b0: 128*Tref, 1'b1: 255*Fref, gated the SPD un-within given range by N*Tref time
  [3:2] adpll_spd_sign_det_cnt — 0,1,2,3 for 16,32,64,127*Tref
  [1:0] adpll_spd_in_range_delay — '0' 128*Tref, '1' 256*Tref, '2' 512*Tref, '3' 1023*Tref, minimum LMS large step induce time
0x290 fcal reset 0x801023
  [23:16] fcal_mom_ini_ext — valid when fcal_mom_ini_ctrl_hw=0
  [12] fcal_phaserr_limit — 1 for 31, 0 for 16, avioding fcal fail at very large frequency error
  [7:6] fcal_mode — 2'b00: binary search, 2'b01: sequential search, 2'b1x: external mode
  [5:4] fcal_clk_period — set the mom_cap search periods, 0,1,2,3 for 7,9,11,13 Tref
  [3] fcal_mom_toggle_cnt — '0' for 8 consecutive fcal periods, '1' for 13
  [2:1] fcal_coarse_pha_threshold — 0,1,2,3 for thresold of 2 3 4 5
  [0] fcal_div_ratio_adj_en — 1'b1 enable the divide ratio adjust after FCAL or at te locking initial state
0x294 adpll_polarity reset 0x101100
  [20] adpll_lp_polarity — ajust the spd output sign bit. '1' for positive gain, '0' for negative gain
  [16] adpll_fcal_polarity — if the Kband is negative number, means capbank code increase, the frequency decrease
  [12] adpll_lms_polarity — set lms polarity
  [8] adpll_lp_mom_polarity — set lp_mom polarity
0x298 adpll_output (reset mask 0xFFC00004)
  [21] adpll_freqerr_det_done ro, [20] adpll_freqerr_ou ro, [19] adpll_freqerr_sign ro, [18] adpll_vctrl_det_done ro, [17] adpll_capcode_ud ro, [16:15] adpll_mom_update_total_ou ro, [14] adpll_capcode_out_range ro, [13] adpll_fcal_done_fsm ro, [12] adpll_spd_lock_fsm ro, [11] adpll_spd_unlock_fsm ro, [10] adpll_mom_update_ou_fsm ro, [9] adpll_mom_update_fail_fsm ro, [8] adpll_vctrl_out_range_fsm ro, [7] adpll_spd_unlock_sign ro, [6:3] adpll_fsm_state ro, [1] adpll_lo_lock ro, [0] adpll_unlock_intrpt ro
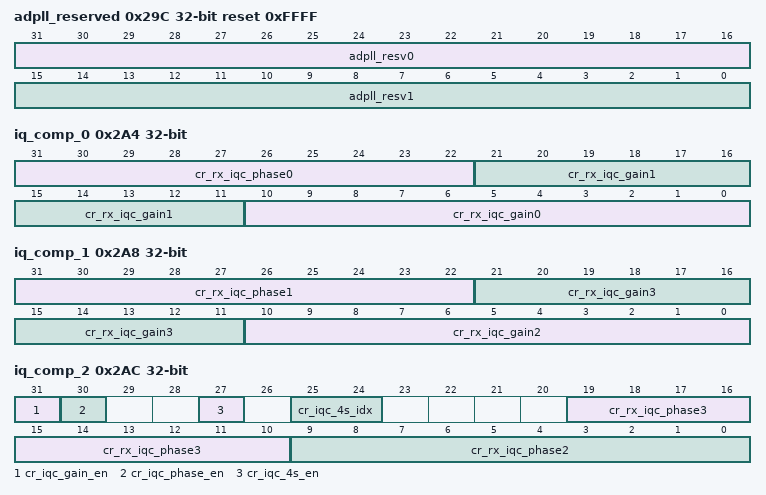
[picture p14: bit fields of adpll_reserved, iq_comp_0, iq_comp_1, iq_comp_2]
0x29C adpll_reserved reset 0xFFFF
  [31:16] adpll_resv0, [15:0] adpll_resv1
0x2A0 rf_reserved reset 0xF03
  [31:0] rf_resv — [31]: used as rbb_trf_en
0x2A4 iq_comp_0
  [31:22] cr_rx_iqc_phase0, [21:11] cr_rx_iqc_gain1, [10:0] cr_rx_iqc_gain0
0x2A8 iq_comp_1
  [31:22] cr_rx_iqc_phase1, [21:11] cr_rx_iqc_gain3, [10:0] cr_rx_iqc_gain2
0x2AC iq_comp_2
  [31] cr_iqc_gain_en, [30] cr_iqc_phase_en, [27] cr_iqc_4s_en, [25:24] cr_iqc_4s_idx, [19:10] cr_rx_iqc_phase3, [9:0] cr_rx_iqc_phase2
0x300 rbb_gain_ctrl0 reset 0x820820
  [29:28] gain_ctrl0_g_rbb1, [26:24] gain_ctrl0_g_rbb2, [23:18] gain_ctrl0_rosdac_i_bw1, [17:12] gain_ctrl0_rosdac_q_bw1, [11:6] gain_ctrl0_rosdac_i_bw0, [5:0] gain_ctrl0_rosdac_q_bw0
0x304 rbb_gain_ctrl1 reset 0x1820820
  [29:28] gain_ctrl1_g_rbb1, [26:24] gain_ctrl1_g_rbb2, [23:18] gain_ctrl1_rosdac_i_bw1, [17:12] gain_ctrl1_rosdac_q_bw1, [11:6] gain_ctrl1_rosdac_i_bw0, [5:0] gain_ctrl1_rosdac_q_bw0
0x308 rbb_gain_ctrl2 reset 0x2820820
  [29:28] gain_ctrl2_g_rbb1, [26:24] gain_ctrl2_g_rbb2, [23:18] gain_ctrl2_rosdac_i_bw1, [17:12] gain_ctrl2_rosdac_q_bw1, [11:6] gain_ctrl2_rosdac_i_bw0, [5:0] gain_ctrl2_rosdac_q_bw0
0x30C rbb_gain_ctrl3 reset 0x3820820
  [29:28] gain_ctrl3_g_rbb1, [26:24] gain_ctrl3_g_rbb2, [23:18] gain_ctrl3_rosdac_i_bw1, [17:12] gain_ctrl3_rosdac_q_bw1, [11:6] gain_ctrl3_rosdac_i_bw0, [5:0] gain_ctrl3_rosdac_q_bw0
0x310 rbb_gain_ctrl4 reset 0x11820820
  [29:28] gain_ctrl4_g_rbb1, [26:24] gain_ctrl4_g_rbb2, [23:18] gain_ctrl4_rosdac_i_bw1, [17:12] gain_ctrl4_rosdac_q_bw1, [11:6] gain_ctrl4_rosdac_i_bw0, [5:0] gain_ctrl4_rosdac_q_bw0
0x314 rbb_gain_ctrl5 reset 0x12820820
  [29:28] gain_ctrl5_g_rbb1, [26:24] gain_ctrl5_g_rbb2, [23:18] gain_ctrl5_rosdac_i_bw1, [17:12] gain_ctrl5_rosdac_q_bw1, [11:6] gain_ctrl5_rosdac_i_bw0, [5:0] gain_ctrl5_rosdac_q_bw0
0x318 rbb_gain_ctrl6 reset 0x13820820
  [29:28] gain_ctrl6_g_rbb1, [26:24] gain_ctrl6_g_rbb2, [23:18] gain_ctrl6_rosdac_i_bw1, [17:12] gain_ctrl6_rosdac_q_bw1, [11:6] gain_ctrl6_rosdac_i_bw0, [5:0] gain_ctrl6_rosdac_q_bw0
0x31C rbb_gain_ctrl7 reset 0x14820820
  [29:28] gain_ctrl7_g_rbb1, [26:24] gain_ctrl7_g_rbb2, [23:18] gain_ctrl7_rosdac_i_bw1, [17:12] gain_ctrl7_rosdac_q_bw1, [11:6] gain_ctrl7_rosdac_i_bw0, [5:0] gain_ctrl7_rosdac_q_bw0
0x320 rbb_gain_ctrl8 reset 0x15820820
  [29:28] gain_ctrl8_g_rbb1, [26:24] gain_ctrl8_g_rbb2, [23:18] gain_ctrl8_rosdac_i_bw1, [17:12] gain_ctrl8_rosdac_q_bw1, [11:6] gain_ctrl8_rosdac_i_bw0, [5:0] gain_ctrl8_rosdac_q_bw0
0x324 rbb_gain_ctrl9 reset 0x23820820
  [29:28] gain_ctrl9_g_rbb1, [26:24] gain_ctrl9_g_rbb2, [23:18] gain_ctrl9_rosdac_i_bw1, [17:12] gain_ctrl9_rosdac_q_bw1, [11:6] gain_ctrl9_rosdac_i_bw0, [5:0] gain_ctrl9_rosdac_q_bw0
0x328 rbb_gain_ctrl10 reset 0x24820820
  [29:28] gain_ctrl10_g_rbb1, [26:24] gain_ctrl10_g_rbb2, [23:18] gain_ctrl10_rosdac_i_bw1, [17:12] gain_ctrl10_rosdac_q_bw1, [11:6] gain_ctrl10_rosdac_i_bw0, [5:0] gain_ctrl10_rosdac_q_bw0
0x32C rbb_gain_ctrl11 reset 0x25820820
  [29:28] gain_ctrl11_g_rbb1, [26:24] gain_ctrl11_g_rbb2, [23:18] gain_ctrl11_rosdac_i_bw1, [17:12] gain_ctrl11_rosdac_q_bw1, [11:6] gain_ctrl11_rosdac_i_bw0, [5:0] gain_ctrl11_rosdac_q_bw0
0x330 rbb_gain_ctrl12 reset 0x26820820
  [29:28] gain_ctrl12_g_rbb1, [26:24] gain_ctrl12_g_rbb2, [23:18] gain_ctrl12_rosdac_i_bw1, [17:12] gain_ctrl12_rosdac_q_bw1, [11:6] gain_ctrl12_rosdac_i_bw0, [5:0] gain_ctrl12_rosdac_q_bw0
0x334 rbb_gain_ctrl13 reset 0x34820820
  [29:28] gain_ctrl13_g_rbb1, [26:24] gain_ctrl13_g_rbb2, [23:18] gain_ctrl13_rosdac_i_bw1, [17:12] gain_ctrl13_rosdac_q_bw1, [11:6] gain_ctrl13_rosdac_i_bw0, [5:0] gain_ctrl13_rosdac_q_bw0
0x338 rbb_gain_ctrl14 reset 0x35820820
  [29:28] gain_ctrl14_g_rbb1, [26:24] gain_ctrl14_g_rbb2, [23:18] gain_ctrl14_rosdac_i_bw1, [17:12] gain_ctrl14_rosdac_q_bw1, [11:6] gain_ctrl14_rosdac_i_bw0, [5:0] gain_ctrl14_rosdac_q_bw0
0x33C rbb_gain_ctrl15 reset 0x36820820
  [29:28] gain_ctrl15_g_rbb1, [26:24] gain_ctrl15_g_rbb2, [23:18] gain_ctrl15_rosdac_i_bw1, [17:12] gain_ctrl15_rosdac_q_bw1, [11:6] gain_ctrl15_rosdac_i_bw0, [5:0] gain_ctrl15_rosdac_q_bw0
0x340 pa_gain_ctrl0 reset 0x88888888
  [4n+3:4n] gain_ctrl{n}_pa_gc (n=0..7)
0x344 pa_gain_ctrl1 reset 0x843300
  [31] adpll_sdm_dith_force_en_ctrl_hw, [30] gain_ctrl_pa_lp_en_zb, [23:20] gain_ctrl_pa_gc_zb, [18:16] gain_ctrl_pa_ldo1_vref_sel_zb, [14:12] pa_cap1_rx, [10:8] pa_cap1_tx, [n] gain_ctrl{n}_pa_lp_en (n=0..7)
0x348 pa_gain_ctrl2 reset 0x44444444
  [4n+2:4n] gain_ctrl{n}_pa_ldo1_vref_sel (n=0..7)
0x34C pa_gain_ctrl3 reset 0x40000000 (reset mask 0x8FFFFF)
  [31] pa_lp_en_hw ro, [30:28] pa_ldo1_vref_sel_hw ro, [27:24] ref_dac_adj_rpt ro, [22:20] tx_gain_index_rpt ro, [4n+2:4n] bz_backoff_db_{n} (n=0..4)
0x350 pa_gain_ctrl4
  [4n+19:4n+16] bz_tempcorr_{n} (n=0..3), [4n+3:4n] bz_chancorr_{n} (n=0..3)
0x354 pa_gain_ctrl5 reset 0xA080604
  [8n+5:8n] bz_nominal_pwr_{n} (n=0..3) — s(6.1) ; -16 ~ +15.5 dBm
0x358 pa_gain_ctrl6 reset 0x12100E0C
  [8n-27:8n-32] bz_nominal_pwr_{n} (n=4..7) — s(6.1) ; -16 ~ +15.5 dBm
0x35C pa_gain_ctrl7 (reset mask 0xFFFFFEFF)
  [8] pa_short_n_hw ro, [n] gain_ctrl{n}_pa_short_n (n=0..7)
0x400 acal_config reset 0x20202020
  [29:24] vco_idac_hh — channel index: 60-80
  [21:16] vco_idac_hl — channel index: 40-58
  [13:8] vco_idac_lh — channel index: 20-38
  [5:0] vco_idac_ll — channel index: 0-18
0x404 lo_config_2402 reset 0x26C
  [12] adpll_sdm_dither_en_2402, [9:0] kcal_ratio_2402
0x408 lo_config_2404 reset 0x26C
  [12] adpll_sdm_dither_en_2404, [9:0] kcal_ratio_2404
0x40C lo_config_2406 reset 0x26C
  [12] adpll_sdm_dither_en_2406, [9:0] kcal_ratio_2406
0x410 lo_config_2408 reset 0x26C
  [12] adpll_sdm_dither_en_2408, [9:0] kcal_ratio_2408
0x414 lo_config_2410 reset 0x26C
  [12] adpll_sdm_dither_en_2410, [9:0] kcal_ratio_2410
0x418 lo_config_2412 reset 0x26C
  [12] adpll_sdm_dither_en_2412, [9:0] kcal_ratio_2412
0x41C lo_config_2414 reset 0x26C
  [12] adpll_sdm_dither_en_2414, [9:0] kcal_ratio_2414
0x420 lo_config_2416 reset 0x26C
  [12] adpll_sdm_dither_en_2416, [9:0] kcal_ratio_2416
0x424 lo_config_2418 reset 0x26C
  [12] adpll_sdm_dither_en_2418, [9:0] kcal_ratio_2418
0x428 lo_config_2420 reset 0x26C
  [12] adpll_sdm_dither_en_2420, [9:0] kcal_ratio_2420
0x42C lo_config_2422 reset 0x26C
  [12] adpll_sdm_dither_en_2422, [9:0] kcal_ratio_2422
0x430 lo_config_2424 reset 0x26C
  [12] adpll_sdm_dither_en_2424, [9:0] kcal_ratio_2424
0x434 lo_config_2426 reset 0x26C
  [12] adpll_sdm_dither_en_2426, [9:0] kcal_ratio_2426
0x438 lo_config_2428 reset 0x26C
  [12] adpll_sdm_dither_en_2428, [9:0] kcal_ratio_2428
0x43C lo_config_2430 reset 0x26C
  [12] adpll_sdm_dither_en_2430, [9:0] kcal_ratio_2430
0x440 lo_config_2432 reset 0x26C
  [12] adpll_sdm_dither_en_2432, [9:0] kcal_ratio_2432
0x444 lo_config_2434 reset 0x26C
  [12] adpll_sdm_dither_en_2434, [9:0] kcal_ratio_2434
0x448 lo_config_2436 reset 0x26C
  [12] adpll_sdm_dither_en_2436, [9:0] kcal_ratio_2436
0x44C lo_config_2438 reset 0x26C
  [12] adpll_sdm_dither_en_2438, [9:0] kcal_ratio_2438
0x450 lo_config_2440 reset 0x26C
  [12] adpll_sdm_dither_en_2440, [9:0] kcal_ratio_2440
0x454 lo_config_2442 reset 0x26C
  [12] adpll_sdm_dither_en_2442, [9:0] kcal_ratio_2442
0x458 lo_config_2444 reset 0x26C
  [12] adpll_sdm_dither_en_2444, [9:0] kcal_ratio_2444
0x45C lo_config_2446 reset 0x26C
  [12] adpll_sdm_dither_en_2446, [9:0] kcal_ratio_2446
0x460 lo_config_2448 reset 0x26C
  [12] adpll_sdm_dither_en_2448, [9:0] kcal_ratio_2448
0x464 lo_config_2450 reset 0x26C
  [12] adpll_sdm_dither_en_2450, [9:0] kcal_ratio_2450
0x468 lo_config_2452 reset 0x26C
  [12] adpll_sdm_dither_en_2452, [9:0] kcal_ratio_2452
0x46C lo_config_2454 reset 0x26C
  [12] adpll_sdm_dither_en_2454, [9:0] kcal_ratio_2454
0x470 lo_config_2456 reset 0x26C
  [12] adpll_sdm_dither_en_2456, [9:0] kcal_ratio_2456
0x474 lo_config_2458 reset 0x26C
  [12] adpll_sdm_dither_en_2458, [9:0] kcal_ratio_2458
0x478 lo_config_2460 reset 0x26C
  [12] adpll_sdm_dither_en_2460, [9:0] kcal_ratio_2460
0x47C lo_config_2462 reset 0x26C
  [12] adpll_sdm_dither_en_2462, [9:0] kcal_ratio_2462
0x480 lo_config_2464 reset 0x26C
  [12] adpll_sdm_dither_en_2464, [9:0] kcal_ratio_2464
0x484 lo_config_2466 reset 0x26C
  [12] adpll_sdm_dither_en_2466, [9:0] kcal_ratio_2466
0x488 lo_config_2468 reset 0x26C
  [12] adpll_sdm_dither_en_2468, [9:0] kcal_ratio_2468
0x48C lo_config_2470 reset 0x26C
  [12] adpll_sdm_dither_en_2470, [9:0] kcal_ratio_2470
0x490 lo_config_2472 reset 0x26C
  [12] adpll_sdm_dither_en_2472, [9:0] kcal_ratio_2472
0x494 lo_config_2474 reset 0x26C
  [12] adpll_sdm_dither_en_2474, [9:0] kcal_ratio_2474
0x498 lo_config_2476 reset 0x26C
  [12] adpll_sdm_dither_en_2476, [9:0] kcal_ratio_2476
0x49C lo_config_2478 reset 0x26C
  [12] adpll_sdm_dither_en_2478, [9:0] kcal_ratio_2478
0x4A0 lo_config_2480 reset 0x26C
  [12] adpll_sdm_dither_en_2480, [9:0] kcal_ratio_2480
0x4A4 lo_config_2405 reset 0x26C
  [12] adpll_sdm_dither_en_2405, [9:0] kcal_ratio_2405
0x4A8 lo_config_2415 reset 0x26C
  [12] adpll_sdm_dither_en_2415, [9:0] kcal_ratio_2415
0x4AC lo_config_2425 reset 0x26C
  [12] adpll_sdm_dither_en_2425, [9:0] kcal_ratio_2425
0x4B0 lo_config_2435 reset 0x26C
  [12] adpll_sdm_dither_en_2435, [9:0] kcal_ratio_2435
0x4B4 lo_config_2445 reset 0x26C
  [12] adpll_sdm_dither_en_2445, [9:0] kcal_ratio_2445
0x4B8 lo_config_2455 reset 0x26C
  [12] adpll_sdm_dither_en_2455, [9:0] kcal_ratio_2455
0x4BC lo_config_2465 reset 0x26C
  [12] adpll_sdm_dither_en_2465, [9:0] kcal_ratio_2465
0x4C0 lo_config_2475 reset 0x26C
  [12] adpll_sdm_dither_en_2475, [9:0] kcal_ratio_2475
0x500 dg_testbus_0 reset 0xBF707 (reset mask 0x0)
  [31:0] rf_testbus_read ro
0x504 dg_testbus_1
  [3:0] rf_testbus_sel
0x508 dg_ppud_0 reset 0x1E9A0000
  [30] ppud_manaual_en — 1:enable pu/ppud/ppud manaual mode
  [29:25] ppud_cnt1 — counter value of ppu
  [24:16] ppud_cnt2 — counter value of pud
0x50C rf_top reset 0x40004 (reset mask 0xFE3FFFFF)
  [31] rf_tx_en_src — 0:from mac, 1:from reg
  [30] rf_tx_en_4s
  [29] rf_rx_en_src — 0:from mac, 1:from reg
  [28] rf_rx_en_4s
  [27] rf_rx_mode_4s_en — 0:from mac, 1:from reg
  [26:25] rf_rx_mode_4s — 0:zigbee 2m, 1:ble 2m 2:ble no coded 1m, 3:ble coded 1m
  [24:22] rf_rx_mode_hw ro — 0:zigbee 2m, 1:ble 2m 2:ble no coded 1m, 3:ble coded 1m
  [21:16] rf_mac_lo_time_offset
  [2] rfckg_afifo_tx_inv
  [1] rfckg_afifo_rxadc_inv
  [0] rfckg_afifo_adpll_inv
0x510 rf_fsm reset 0x5C200A00 (reset mask 0xFFFF8FFF)
  [31:26] rf_fsm_tx_afifo_dly_time
  [25] rf_fsm_tx_afifo_4s_en
  [24] rf_fsm_tx_afifo_4s
  [23] rf_fsm_rx_afifo_4s_en
  [22] rf_fsm_rx_afifo_4s
  [21] rf_fsm_en
  [20] rf_fsm_st_4s_en
  [18:16] rf_fsm_st_4s
  [14:12] rf_fsm_state ro — 0: SB, 1: LOTX, 2: TX, 3:LORX, 4:RX
  [11:0] rf_fsm_lo_time
0x514 rf_singen_0 reset 0x10001
  [31] singen_en — 1: singen enable
  [30:29] singen_clkdiv_n — div by 1024^n
  [28] singen_unsign_en — 0:signed output 1:unsigned output
  [25:16] singen_inc_step0 — 1st tone step
  [9:0] singen_inc_step1 — 2nd tone step
0x518 rf_singen_1 reset 0x10001
  [31:28] singen_mode_i — 0: single-tone, 1: two-tone, 2: ramp_up, 3: ramp_down, 4: LFSR24, 5: LFSR16, 6: LFSR12, 7: LFSR8
  [25:16] singen_clkdiv_i — 1x~1/1024x, default 10'd1
  [15:12] singen_mode_q — 0: single-tone, 1: two-tone, 2: ramp_up, 3: ramp_down, 4: LFSR24, 5: LFSR16, 6: LFSR12, 7: LFSR8
  [9:0] singen_clkdiv_q — 1x~1/1024x, default 10'd1
0x51C rf_singen_2 reset 0x3FF
  [31:22] singen_start_addr0_i — singen table start address 0
  [21:12] singen_start_addr1_i — singen table start address 1
  [10:0] singen_gain_i — 2x~1/1024x, default 11'd1023
0x520 rf_singen_3 reset 0x3FF
  [31:22] singen_start_addr0_q — singen table start address 0
  [21:12] singen_start_addr1_q — singen table start address 1
  [10:0] singen_gain_q — 2x~1/1024x, default 11'd1023
0x524 rf_singen_4
  [28] singen_fix_en_i — 1: enable fix value
  [27:16] singen_fix_i — output constant value
  [12] singen_fix_en_q — 1: enable fix value
  [11:0] singen_fix_q — output constant value
0x528 rf_sram_ctrl0 (reset mask 0xFFFE)
  [31:16] rf_sram_done_cnt ro
  [8] rf_sram_manu_en_hclk
  [5:4] rf_sram_mode — 2'd0:sram -> dac, 2'd1:adc -> sram, 2'd2:adpll -> sram
  [3] rf_sram_sts_clr — 1:clear adc fifo status
  [2] rf_sram_loop_en — 1:loop enable
  [1] rf_sram_en — 1:enable adc sram record
  [0] rf_sram_done ro — 1:done
0x52C rf_sram_ctrl1 reset 0x6000FFFF
  [31:16] rf_sram_addr_start — start address(4-byte address)
  [15:0] rf_sram_addr_end — end address(4-byte address)
0x530 rf_sram_ctrl2 reset not defined
  [31:0] rf_sram_sts ro — async fifo status
0x534 rf_test_mode (reset mask 0xFFFFF000)
  [30] rf_test_mode_en, [29] dacout_4s_sram_en, [28] dacout_4s_en, [27:16] dacout_4s, [11:0] dacout_hw ro
0x538 rf_rx_pulse_filter reset 0x1FC0F
  [21] pf_en_i, [20] pf_en_q, [18:10] pf_th1, [8:0] pf_th2
0x53C rf_fsm1 reset 0x357
  [9] rxadc_clk_div_sel_ctrl_hw, [8] rf_apply_pre_pu_pa, [7:0] rf_fsm_rx_afifo_dly_time
0x540 rf_cal0 reset 0x1002 (reset mask 0xFFBFFFFF)
  [31:28] cr_cal_init_time, [27:24] cr_cal_est_time, [23] cr_cal_en, [22] ro_cal_done ro, [21:12] cr_cal_ang0, [9:0] cr_cal_ang1
0x544 rf_cal1 reset not defined
  [31:16] ro_pos0_i ro, [15:0] ro_pos0_q ro
0x548 rf_cal2 reset not defined
  [31:16] ro_neg0_i ro, [15:0] ro_neg0_q ro
0x54C rf_cal3 reset not defined
  [31:16] ro_pos1_i ro, [15:0] ro_pos1_q ro
0x550 rf_cal4 reset not defined
  [31:16] ro_neg1_i ro, [15:0] ro_neg1_q ro
0x554 rf_cal5 reset not defined
  [31:16] ro_dc_i ro, [15:0] ro_dc_q ro
0x558 rf_cal6 reset not defined
  [31:16] ro_pwr_i ro, [15:0] ro_pwr_q ro
0x55C rf_dig_rsv reset 0xFFFF0000
  [31:0] cfg_rf_dig_rsv
0x560 rf_ILA_ctrl0 (reset mask 0x7FFFFFFF)
  [31] ILA_done ro, [30:28] cfg_ILA_data_src_sel, [27:26] cfg_ILA_trig_op_sel3, [25:24] cfg_ILA_trig_op_sel2, [23:22] cfg_ILA_trig_op_sel1, [21] cfg_ILA_data_src_to_sram, [20] cfg_ILA_force_stop wo, [18:16] cfg_ILA_trig_src_sel3, [14:12] cfg_ILA_trig_src_sel2, [10:8] cfg_ILA_trig_src_sel1, [7:4] cfg_ILA_trig_ph_op, [3:1] cfg_ILA_deci, [0] cfg_ILA_en
{0x560+4i} rf_ILA_ctrl{i} (i=1..3)
  [31:0] cfg_ILA_trig_mask_sel{i}
{0x560+4i} rf_ILA_ctrl{i} (i=4..6)
  [31:0] cfg_ILA_trig_target_sel{i-3}
0x57C rf_ILA_ctrl7
  [31:0] cfg_ILA_end_cnt
0x580 rf_ILA_ctrl8 (reset mask 0xFFFF0000)
  [15:0] rf_sram_adc_addr_keep ro
0x584 rf_ILA_ctrl9
  [31:4] cfg_ILA_reserved, [0] rf_sram_adc_wr_data_sel
